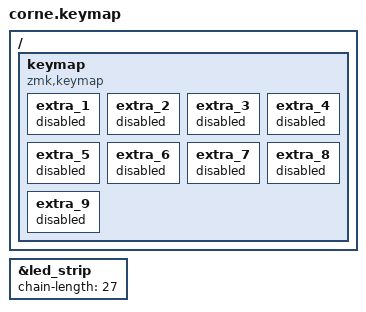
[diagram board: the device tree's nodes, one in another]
/*
 * Copyright (c) 2020 The ZMK Contributors
 *
 * SPDX-License-Identifier: MIT
 */

#include <behaviors.dtsi>
#include <dt-bindings/zmk/keys.h>
#include <dt-bindings/zmk/bt.h>
#include <dt-bindings/zmk/outputs.h>
#include <dt-bindings/zmk/ext_power.h>
#include <dt-bindings/led/led.h>
#include <dt-bindings/zmk/backlight.h>
#include <dt-bindings/zmk/rgb.h>
#include <dt-bindings/zmk/reset.h>

&led_strip {
    chain-length = <27>;
};

/ {
    keymap {
        compatible = "zmk,keymap";

        extra_1 {
            status = "reserved";
        };

        extra_2 {
            status = "reserved";
        };

        extra_3 {
            status = "reserved";
        };

        extra_4 {
            status = "reserved";
        };

        extra_5 {
            status = "reserved";
        };

        extra_6 {
            status = "reserved";
        };

        extra_7 {
            status = "reserved";
        };

        extra_8 {
            status = "reserved";
        };

        extra_9 {
            status = "reserved";
        };
    };
};
